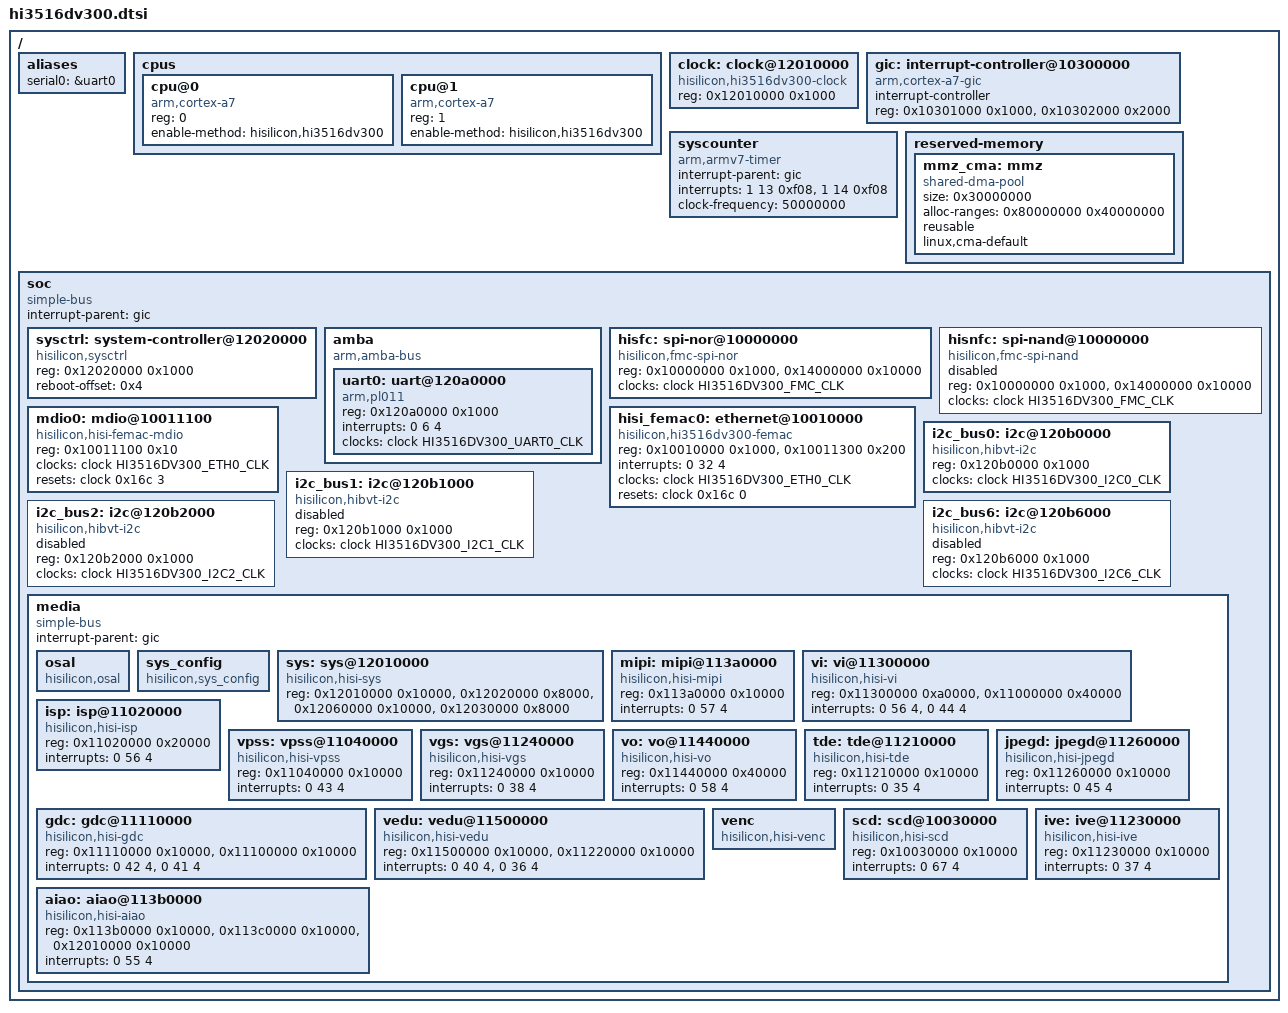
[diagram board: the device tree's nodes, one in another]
// SPDX-License-Identifier: (GPL-2.0-or-later OR MIT)
/*
 * Hi3516DV300 / Hi3516AV300 / Hi3516CV500 SoC family.
 *
 * Minimal DTS for modern kernel boot. Hardware peripherals (ISP, VPSS,
 * VENC, MMZ, etc.) are initialized by vendor OSAL/blob modules at
 * runtime — only the boot-critical nodes are defined here.
 */

#include <dt-bindings/clock/hi3516dv300-clock.h>
/ {
	#address-cells = <1>;
	#size-cells = <1>;

	aliases {
		serial0 = &uart0;
	};

	cpus {
		#address-cells = <1>;
		#size-cells = <0>;

		cpu@0 {
			device_type = "cpu";
			compatible = "arm,cortex-a7";
			reg = <0>;
			enable-method = "hisilicon,hi3516dv300";
		};

		cpu@1 {
			device_type = "cpu";
			compatible = "arm,cortex-a7";
			reg = <1>;
			enable-method = "hisilicon,hi3516dv300";
		};
	};

	clock: clock@12010000 {
		compatible = "hisilicon,hi3516dv300-clock", "syscon";
		#address-cells = <1>;
		#size-cells = <1>;
		#clock-cells = <1>;
		#reset-cells = <2>;
		reg = <0x12010000 0x1000>;
	};

	gic: interrupt-controller@10300000 {
		compatible = "arm,cortex-a7-gic";
		#interrupt-cells = <3>;
		#address-cells = <0>;
		interrupt-controller;
		reg = <0x10301000 0x1000>, <0x10302000 0x2000>;
	};

	syscounter {
		compatible = "arm,armv7-timer";
		interrupt-parent = <&gic>;
		interrupts = <1 13 0xf08>,
			<1 14 0xf08>;
		clock-frequency = <50000000>;
	};

	/* CMA as the base allocator: reusable + linux,cma-default makes
	 * dma_alloc and HiSilicon MMZ pull from this pool, while letting
	 * the kernel borrow the same pages for movable allocations when
	 * they are not pinned for DMA. Sized for 4K capture pipelines
	 * (IMX415 3840x2160 + multi-channel encoders).
	 * See OpenIPC wiki en/memory-tuning.md.
	 */
	reserved-memory {
		#address-cells = <1>;
		#size-cells = <1>;
		ranges;

		mmz_cma: mmz {
			compatible = "shared-dma-pool";
			size = <0x30000000>; /* 768 MiB */
			alloc-ranges = <0x80000000 0x40000000>;
			reusable;
			linux,cma-default;
		};
	};

	soc {
		#address-cells = <1>;
		#size-cells = <1>;
		compatible = "simple-bus";
		interrupt-parent = <&gic>;
		ranges;

		sysctrl: system-controller@12020000 {
			compatible = "hisilicon,sysctrl";
			reg = <0x12020000 0x1000>;
			reboot-offset = <0x4>;
			#clock-cells = <1>;
		};

		amba {
			#address-cells = <1>;
			#size-cells = <1>;
			compatible = "arm,amba-bus";
			ranges;

			uart0: uart@120a0000 {
				compatible = "arm,pl011", "arm,primecell";
				reg = <0x120a0000 0x1000>;
				interrupts = <0 6 4>;
				clocks = <&clock HI3516DV300_UART0_CLK>;
				clock-names = "apb_pclk";
				status = "okay";
			};
		};

		/* SPI NOR flash — boot device */
		hisfc: spi-nor@10000000 {
			compatible = "hisilicon,fmc-spi-nor";
			reg = <0x10000000 0x1000>, <0x14000000 0x10000>;
			reg-names = "control", "memory";
			clocks = <&clock HI3516DV300_FMC_CLK>;
			#address-cells = <1>;
			#size-cells = <0>;
		};

		hisnfc: spi-nand@10000000 {
			compatible = "hisilicon,fmc-spi-nand";
			reg = <0x10000000 0x1000>, <0x14000000 0x10000>;
			reg-names = "control", "memory";
			clocks = <&clock HI3516DV300_FMC_CLK>;
			#address-cells = <1>;
			#size-cells = <0>;
			status = "disabled";
		};

		mdio0: mdio@10011100 {
			compatible = "hisilicon,hisi-femac-mdio";
			reg = <0x10011100 0x10>;
			clocks = <&clock HI3516DV300_ETH0_CLK>;
			clock-names = "mdio";
			resets = <&clock 0x16c 3>;
			reset-names = "external-phy";
			#address-cells = <1>;
			#size-cells = <0>;
		};

		hisi_femac0: ethernet@10010000 {
			compatible = "hisilicon,hi3516dv300-femac",
				"hisilicon,hisi-femac-v2";
			reg = <0x10010000 0x1000>,<0x10011300 0x200>;
			interrupts = <0 32 4>;
			clocks = <&clock HI3516DV300_ETH0_CLK>;
			resets = <&clock 0x16c 0>;
			reset-names = "mac";
		};

		i2c_bus0: i2c@120b0000 {
			compatible = "hisilicon,hibvt-i2c";
			reg = <0x120b0000 0x1000>;
			clocks = <&clock HI3516DV300_I2C0_CLK>;
		};

		i2c_bus1: i2c@120b1000 {
			compatible = "hisilicon,hibvt-i2c";
			reg = <0x120b1000 0x1000>;
			clocks = <&clock HI3516DV300_I2C1_CLK>;
			status = "disabled";
		};

		i2c_bus2: i2c@120b2000 {
			compatible = "hisilicon,hibvt-i2c";
			reg = <0x120b2000 0x1000>;
			clocks = <&clock HI3516DV300_I2C2_CLK>;
			status = "disabled";
		};

		i2c_bus6: i2c@120b6000 {
			compatible = "hisilicon,hibvt-i2c";
			reg = <0x120b6000 0x1000>;
			clocks = <&clock HI3516DV300_I2C6_CLK>;
			status = "disabled";
		};

		/* Vendor media subsystem — initialized by OSAL modules.
		 * sys_config does pinmux + clock setup; the rest are matched
		 * by hi3516cv500 init wrappers in OpenIPC/openhisilicon. */
		media {
			#address-cells = <1>;
			#size-cells = <1>;
			compatible = "simple-bus";
			interrupt-parent = <&gic>;
			ranges;

			osal: osal {
				compatible = "hisilicon,osal";
			};

			sys_config: sys_config {
				compatible = "hisilicon,sys_config";
			};

			sys: sys@12010000 {
				compatible = "hisilicon,hisi-sys";
				reg = <0x12010000 0x10000>, <0x12020000 0x8000>,
					<0x12060000 0x10000>, <0x12030000 0x8000>;
				reg-names = "crg", "sys", "ddr", "misc";
			};

			mipi: mipi@113a0000 {
				compatible = "hisilicon,hisi-mipi";
				reg = <0x113a0000 0x10000>;
				reg-names = "mipi_rx";
				interrupts = <0 57 4>;
				interrupt-names = "mipi_rx";
			};

			vi: vi@11300000 {
				compatible = "hisilicon,hisi-vi";
				reg = <0x11300000 0xa0000>, <0x11000000 0x40000>;
				reg-names = "VI_CAP0", "VI_PROC0";
				interrupts = <0 56 4>, <0 44 4>;
				interrupt-names = "VI_CAP0", "VI_PROC0";
			};

			isp: isp@11020000 {
				compatible = "hisilicon,hisi-isp";
				reg = <0x11020000 0x20000>;
				reg-names = "ISP";
				interrupts = <0 56 4>;
				interrupt-names = "ISP";
			};

			vpss: vpss@11040000 {
				compatible = "hisilicon,hisi-vpss";
				reg = <0x11040000 0x10000>;
				reg-names = "vpss0";
				interrupts = <0 43 4>;
				interrupt-names = "vpss0";
			};

			vgs: vgs@11240000 {
				compatible = "hisilicon,hisi-vgs";
				reg = <0x11240000 0x10000>;
				reg-names = "vgs0";
				interrupts = <0 38 4>;
				interrupt-names = "vgs0";
			};

			vo: vo@11440000 {
				compatible = "hisilicon,hisi-vo";
				reg = <0x11440000 0x40000>;
				reg-names = "vo";
				interrupts = <0 58 4>;
				interrupt-names = "vo";
			};

			tde: tde@11210000 {
				compatible = "hisilicon,hisi-tde";
				reg = <0x11210000 0x10000>;
				reg-names = "tde";
				interrupts = <0 35 4>;
				interrupt-names = "tde_osr_isr";
			};

			gdc: gdc@11110000 {
				compatible = "hisilicon,hisi-gdc";
				reg = <0x11110000 0x10000>, <0x11100000 0x10000>;
				reg-names = "gdc", "nnie0";
				interrupts = <0 42 4>, <0 41 4>;
				interrupt-names = "gdc", "nnie0";
			};

			jpegd: jpegd@11260000 {
				compatible = "hisilicon,hisi-jpegd";
				reg = <0x11260000 0x10000>;
				reg-names = "jpegd";
				interrupts = <0 45 4>;
				interrupt-names = "jpegd";
			};

			vedu: vedu@11500000 {
				compatible = "hisilicon,hisi-vedu";
				reg = <0x11500000 0x10000>, <0x11220000 0x10000>;
				reg-names = "vedu0", "jpge";
				interrupts = <0 40 4>, <0 36 4>;
				interrupt-names = "vedu0", "jpge";
			};

			venc: venc {
				compatible = "hisilicon,hisi-venc";
			};

			scd: scd@10030000 {
				compatible = "hisilicon,hisi-scd";
				reg = <0x10030000 0x10000>;
				reg-names = "scd";
				interrupts = <0 67 4>;
				interrupt-names = "scd";
			};

			aiao: aiao@113b0000 {
				compatible = "hisilicon,hisi-aiao";
				reg = <0x113b0000 0x10000>, <0x113c0000 0x10000>, <0x12010000 0x10000>;
				reg-names = "aiao", "acodec", "crg";
				interrupts = <0 55 4>;
				interrupt-names = "AIO";
			};

			ive: ive@11230000 {
				compatible = "hisilicon,hisi-ive";
				reg = <0x11230000 0x10000>;
				reg-names = "ive";
				interrupts = <0 37 4>;
				interrupt-names = "ive";
			};
		};
	};
};
